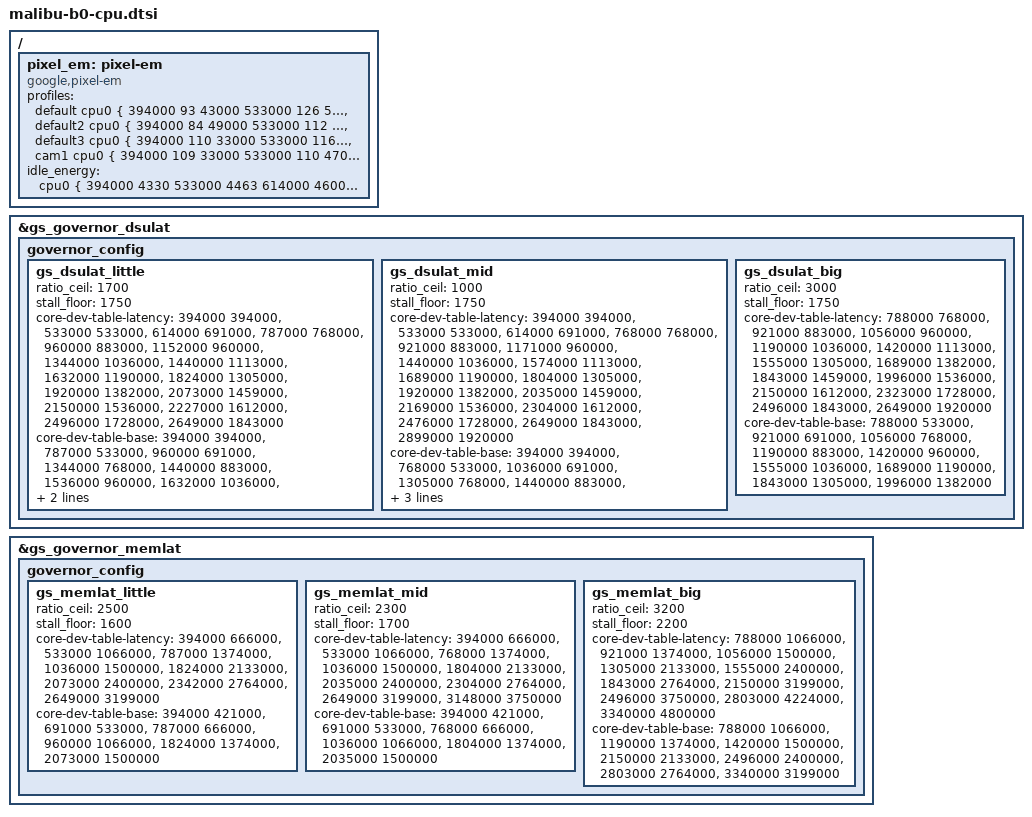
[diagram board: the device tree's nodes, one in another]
// SPDX-License-Identifier: GPL-2.0 OR BSD-3-Clause

&gs_governor_dsulat {
	governor_config {
		gs_dsulat_little {
			ratio_ceil = <1700>;
			stall_floor = <1750>;
			core-dev-table-latency =
			/* Little CPU    DSU */
			<  394000	 394000 >,
			<  533000	 533000 >,
			<  614000	 691000 >,
			<  787000	 768000 >,
			<  960000	 883000 >,
			< 1152000	 960000 >,
			< 1344000	1036000 >,
			< 1440000	1113000 >,
			< 1632000	1190000 >,
			< 1824000	1305000 >,
			< 1920000	1382000 >,
			< 2073000	1459000 >,
			< 2150000	1536000 >,
			< 2227000	1612000 >,
			< 2496000	1728000 >,
			< 2649000	1843000 >;

			core-dev-table-base =
			/* Little CPU    DSU */
			<  394000	 394000 >,
			<  787000	 533000 >,
			<  960000	 691000 >,
			< 1344000	 768000 >,
			< 1440000	 883000 >,
			< 1536000	 960000 >,
			< 1632000	1036000 >,
			< 1824000	1113000 >,
			< 1920000	1190000 >,
			< 2073000	1305000 >,
			< 2150000	1382000 >;
		};
		gs_dsulat_mid {
			ratio_ceil = <1000>;
			stall_floor = <1750>;
			core-dev-table-latency =
			/* Mid CPU       DSU */
			<  394000	 394000 >,
			<  533000	 533000 >,
			<  614000	 691000 >,
			<  768000	 768000 >,
			<  921000	 883000 >,
			< 1171000	 960000 >,
			< 1440000	1036000 >,
			< 1574000	1113000 >,
			< 1689000	1190000 >,
			< 1804000	1305000 >,
			< 1920000	1382000 >,
			< 2035000	1459000 >,
			< 2169000	1536000 >,
			< 2304000	1612000 >,
			< 2476000	1728000 >,
			< 2649000	1843000 >,
			< 2899000	1920000 >;

			core-dev-table-base =
			/* Mid CPU       DSU */
			<  394000	 394000 >,
			<  768000	 533000 >,
			< 1036000	 691000 >,
			< 1305000	 768000 >,
			< 1440000	 883000 >,
			< 1574000	 960000 >,
			< 1689000	1036000 >,
			< 1804000	1113000 >,
			< 1920000	1190000 >,
			< 2035000	1305000 >,
			< 2169000	1382000 >;

		};
		gs_dsulat_big {
			ratio_ceil = <3000>;
			stall_floor = <1750>;
			core-dev-table-latency =
			/* Big CPU       DSU */
			<  788000	 768000 >,
			<  921000	 883000 >,
			< 1056000	 960000 >,
			< 1190000	1036000 >,
			< 1420000	1113000 >,
			< 1555000	1305000 >,
			< 1689000	1382000 >,
			< 1843000	1459000 >,
			< 1996000	1536000 >,
			< 2150000	1612000 >,
			< 2323000	1728000 >,
			< 2496000	1843000 >,
			< 2649000	1920000 >;

			core-dev-table-base =
			/* Big CPU       DSU */
			<  788000	 533000 >,
			<  921000	 691000 >,
			< 1056000	 768000 >,
			< 1190000	 883000 >,
			< 1420000	 960000 >,
			< 1555000	1036000 >,
			< 1689000	1190000 >,
			< 1843000	1305000 >,
			< 1996000	1382000 >;
		};
	};
};

&gs_governor_memlat {
	governor_config {
		gs_memlat_little {
			ratio_ceil = <2500>;
			stall_floor = <1600>;
			core-dev-table-latency =
			/* LITTLE CPU	 GMC */
			<  394000	 666000 >,
			<  533000	1066000 >,
			<  787000	1374000 >,
			< 1036000	1500000 >,
			< 1824000	2133000 >,
			< 2073000	2400000 >,
			< 2342000	2764000 >,
			< 2649000	3199000 >;

			core-dev-table-base =
			/* LITTLE CPU    GMC */
			<  394000	 421000 >,
			<  691000	 533000 >,
			<  787000	 666000 >,
			<  960000	1066000 >,
			< 1824000	1374000 >,
			< 2073000	1500000 >;

		};
		gs_memlat_mid {
			ratio_ceil = <2300>;
			stall_floor = <1700>;
			core-dev-table-latency =
			/* MID CPU	 GMC */
			<  394000	 666000 >,
			<  533000	1066000 >,
			<  768000	1374000 >,
			< 1036000	1500000 >,
			< 1804000	2133000 >,
			< 2035000	2400000 >,
			< 2304000	2764000 >,
			< 2649000	3199000 >,
			< 3148000	3750000 >;

			core-dev-table-base =
			/* MID CPU    	 GMC */
			<  394000	 421000 >,
			<  691000	 533000 >,
			<  768000	 666000 >,
			< 1036000	1066000 >,
			< 1804000	1374000 >,
			< 2035000	1500000 >;

		};
		gs_memlat_big {
			ratio_ceil = <3200>;
			stall_floor = <2200>;
			core-dev-table-latency =
			/* BIG CPU    	 GMC */
			<  788000	1066000 >,
			<  921000	1374000 >,
			< 1056000	1500000 >,
			< 1305000	2133000 >,
			< 1555000	2400000 >,
			< 1843000	2764000 >,
			< 2150000	3199000 >,
			< 2496000	3750000 >,
			< 2803000	4224000 >,
			< 3340000	4800000 >;

			core-dev-table-base =
			/* BIG CPU    	GMC */
			<  788000	1066000 >,
			< 1190000	1374000 >,
			< 1420000	1500000 >,
			< 2150000	2133000 >,
			< 2496000	2400000 >,
			< 2803000	2764000 >,
			< 3340000	3199000 >;
		};
	};
};

/ {
	pixel_em: pixel-em {
		compatible = "google,pixel-em";
		profiles =
			"default
				cpu0 {
				394000 93 43000
				533000 126 58000
				614000 143 74000
				691000 160 82000
				787000 183 91000
				883000 205 102000
				960000 223 112000
				1036000 242 127000
				1152000 269 140000
				1248000 292 163000
				1344000 315 181000
				1440000 339 208000
				1536000 363 231000
				1632000 386 256000
				1728000 409 294000
				1824000 432 320000
				1920000 454 357000
				2073000 491 413000
				2150000 509 431000
				2227000 527 477000
				2342000 554 540000
				2496000 591 622000
				2649000 627 708000
				}
				cpu2 {
				394000 93 50000
				533000 126 70000
				614000 145 86000
				691000 163 96000
				768000 180 104000
				844000 198 114000
				921000 215 126000
				1036000 244 148000
				1171000 275 174000
				1305000 307 199000
				1440000 339 231000
				1574000 371 264000
				1689000 398 294000
				1804000 425 325000
				1920000 454 377000
				2035000 482 420000
				2169000 514 469000
				2304000 546 513000
				2476000 586 614000
				2649000 627 729000
				2899000 686 905000
				3148000 746 1141000
				3379000 800 1447000
				}
				cpu6 {
				788000 233 362000
				921000 269 388000
				1056000 302 467000
				1190000 327 536000
				1305000 358 605000
				1420000 409 671000
				1555000 451 779000
				1689000 484 885000
				1843000 537 1008000
				1996000 566 1141000
				2150000 615 1295000
				2323000 684 1510000
				2496000 745 1715000
				2649000 795 1968000
				2803000 814 2192000
				3033000 846 2644000
				3340000 970 3294000
				3571000 1020 4498000
				3782000 1021 4593000
				3898000 1022 4694000
				4013000 1023 4795000
				4109000 1024 4896000
				}",
			"default2
				cpu0 {
				394000 84 49000
				533000 112 64000
				614000 135 74000
				691000 151 81000
				787000 172 90000
				883000 192 103000
				960000 208 114000
				1036000 226 128000
				1152000 250 143000
				1248000 271 164000
				1344000 292 181000
				1440000 313 206000
				1536000 333 226000
				1632000 352 252000
				1728000 373 281000
				1824000 394 312000
				1920000 413 347000
				2073000 444 394000
				2150000 461 408000
				2227000 475 455000
				2342000 497 513000
				2496000 527 592000
				2649000 557 670000
				}
				cpu2 {
				394000 84 59000
				533000 113 78000
				614000 137 86000
				691000 153 95000
				768000 169 104000
				844000 186 112000
				921000 202 126000
				1036000 228 151000
				1171000 256 175000
				1305000 285 198000
				1440000 314 226000
				1574000 342 256000
				1689000 367 288000
				1804000 390 311000
				1920000 414 358000
				2035000 437 401000
				2169000 463 449000
				2304000 490 483000
				2476000 525 575000
				2649000 557 670000
				2899000 607 824000
				3148000 653 1062000
				3379000 695 1333000
				}
				cpu6 {
				788000 256 349000
				921000 294 396000
				1056000 336 472000
				1190000 378 546000
				1305000 414 609000
				1420000 449 671000
				1555000 490 770000
				1689000 531 866000
				1843000 576 981000
				1996000 619 1123000
				2150000 663 1256000
				2323000 713 1456000
				2496000 760 1651000
				2649000 804 1880000
				2803000 845 2099000
				3033000 905 2580000
				3340000 983 3174000
				3571000 1020 4268000
				3782000 1021 4368000
				3898000 1022 4468000
				4013000 1023 4568000
				4109000 1024 4668000
				}",
			"default3
				cpu0 {
				394000 110 33000
				533000 116 47000
				614000 117 74000
				691000 131 81000
				787000 149 90000
				883000 167 103000
				960000 181 114000
				1036000 196 128000
				1152000 217 143000
				1248000 236 164000
				1344000 254 181000
				1440000 272 206000
				1536000 289 226000
				1632000 306 252000
				1728000 324 281000
				1824000 342 312000
				1920000 359 347000
				2073000 386 394000
				2150000 401 408000
				2227000 413 455000
				2342000 432 513000
				2496000 458 592000
				2649000 484 670000
				}
				cpu2 {
				394000 110 33000
				533000 118 47000
				614000 119 86000
				691000 133 95000
				768000 147 104000
				844000 162 112000
				921000 176 126000
				1036000 198 151000
				1171000 222 175000
				1305000 248 198000
				1440000 273 226000
				1574000 297 256000
				1689000 319 288000
				1804000 339 311000
				1920000 360 358000
				2035000 380 401000
				2169000 402 449000
				2304000 426 483000
				2476000 456 575000
				2649000 484 670000
				2899000 528 824000
				3148000 568 1062000
				3379000 604 1333000
				}
				cpu6 {
				788000 255 349000
				921000 256 396000
				1056000 292 472000
				1190000 329 546000
				1305000 360 609000
				1420000 390 671000
				1555000 426 770000
				1689000 461 866000
				1843000 501 981000
				1996000 538 1123000
				2150000 576 1256000
				2323000 620 1456000
				2496000 660 1651000
				2649000 699 1880000
				2803000 734 2099000
				3033000 787 2580000
				3340000 854 3174000
				3571000 886 4268000
				3782000 940 4787000
				3898000 970 5205000
				4013000 999 5643000
				4109000 1024 6048000
				}
			",
			"cam1
				cpu0 {
				394000 109 33000
				533000 110 47000
				614000 111 56000
				691000 124 65000
				787000 142 77000
				883000 159 90000
				960000 173 100000
				1036000 186 109000
				1152000 207 132000
				1248000 225 151000
				1344000 242 173000
				1440000 259 197000
				1536000 276 221000
				1632000 294 257000
				1728000 311 288000
				1824000 328 325000
				1920000 346 376000
				2073000 373 440000
				2150000 387 476000
				2227000 401 530000
				2342000 422 593000
				2496000 449 720000
				2649000 501 1641000
				}
				cpu2 {
				394000 109 33000
				533000 110 47000
				614000 111 56000
				691000 124 65000
				768000 138 74000
				844000 152 86000
				921000 166 95000
				1036000 186 109000
				1171000 211 134000
				1305000 235 167000
				1440000 259 208000
				1574000 283 238000
				1689000 304 275000
				1804000 325 315000
				1920000 346 351000
				2035000 366 402000
				2169000 390 471000
				2304000 415 541000
				2476000 446 648000
				2649000 477 758000
				2899000 522 990000
				3148000 567 1121000
				3379000 639 2192000
				}
				cpu6 {
				788000 263 349000
				921000 281 465000
				1056000 322 556000
				1190000 363 647000
				1305000 398 714000
				1420000 433 792000
				1555000 474 888000
				1689000 515 1034000
				1843000 562 1152000
				1996000 609 1291000
				2150000 656 1525000
				2323000 709 1715000
				2496000 761 1969000
				2649000 808 2200000
				2803000 855 2342000
				3033000 925 2884000
				3340000 1019 3615000
				3571000 1020 3659000
				3782000 1021 3719000
				3898000 1022 4694000
				4013000 1023 4795000
				4109000 1024 4896000
				}
			";
			idle_energy =
			"
				cpu0 {
				394000 4330
				533000 4463
				614000 4600
				691000 4741
				787000 4883
				883000 4974
				960000 5065
				1036000 5915
				1152000 6765
				1248000 7092
				1344000 7418
				1440000 8336
				1536000 9253
				1632000 9787
				1728000 10321
				1824000 10766
				1920000 11211
				2073000 13334
				2150000 15456
				2227000 16100
				2342000 16745
				2496000 16796
				2649000 16847
				}
				cpu2 {
				394000 4663
				533000 4851
				614000 5047
				691000 5250
				768000 5454
				844000 5658
				921000 5862
				1036000 6398
				1171000 6935
				1305000 8408
				1440000 9881
				1574000 10747
				1689000 11613
				1804000 11613
				1920000 11613
				2035000 14189
				2169000 16764
				2304000 16764
				2476000 16764
				2649000 23628
				2899000 30491
				3148000 39348
				3379000 50777
				}
				cpu6 {
				788000 182276
				921000 195892
				1056000 210526
				1190000 225160
				1305000 242747
				1420000 260334
				1555000 272220
				1689000 284107
				1843000 309619
				1996000 335130
				2150000 382543
				2323000 429955
				2496000 453380
				2649000 476805
				2803000 558763
				3033000 640720
				3340000 645881
				3571000 651042
				3782000 656243
				3898000 661487
				4013000 666772
				4109000 672099
				}
			";
	};
};
